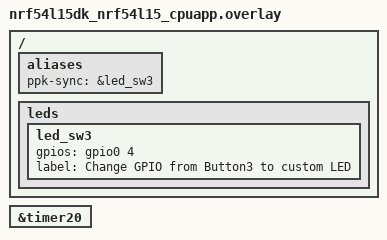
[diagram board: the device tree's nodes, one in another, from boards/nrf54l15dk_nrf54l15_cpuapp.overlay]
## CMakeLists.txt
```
#
# Copyright (c) 2025 Nordic Semiconductor ASA
#
# SPDX-License-Identifier: LicenseRef-Nordic-5-Clause
#

cmake_minimum_required(VERSION 3.20.0)
find_package(Zephyr REQUIRED HINTS $ENV{ZEPHYR_BASE})
project(rram_low_latency)

target_sources(app PRIVATE src/main.c)
```

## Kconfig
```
#
# Copyright (c) 2026 Nordic Semiconductor ASA
#
# SPDX-License-Identifier: LicenseRef-Nordic-5-Clause
#

choice RRAMC_LOW_LATENCY_METHOD
	prompt "Select method that sets RRAMC low latency"
	default RRAMC_POWER_MODE

config RRAMC_POWER_MODE
	bool "RRAMC mode is set to low penalty/high current consumption"

config RRAMC_PPI_WAKEUP
	bool "RRAMC is waken up just before registered event"

endchoice

source "Kconfig.zephyr"
```

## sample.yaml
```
common:
  sysbuild: true
  tags:
    - ci_tests_benchmarks_current_consumption
    - ppk_power_measure
  harness: pytest
  harness_config:
    fixture: ppk_power_measure
    pytest_root:
      - "${CUSTOM_ROOT_TEST_DIR}/test_measure_power_consumption.py::test_measure_and_data_dump_rram_low_latency"
  platform_allow:
    - nrf54l15dk/nrf54l15/cpuapp
    - nrf54lm20dk/nrf54lm20a/cpuapp
    - nrf54lm20dk/nrf54lm20b/cpuapp
    - nrf54ls05dk/nrf54ls05a/cpuapp
    - nrf54ls05dk/nrf54ls05b/cpuapp
    - nrf54lv10dk/nrf54lv10a/cpuapp
    - nrf54lc10dk/nrf54lc10a/cpuapp
  integration_platforms:
    - nrf54l15dk/nrf54l15/cpuapp
tests:
  # Set NRF_RRAMC_LP_STANDBY mode
  # this configuration shall have higher power consumption
  # due to RRAM being powered on for all the time
  benchmarks.current_consumption.rram_low_latency.standby_mode: {}
  # use GRTC and DPPI to wakeup RRAM just before expected event
  benchmarks.current_consumption.rram_low_latency.pre_wake:
    extra_configs:
      - CONFIG_RRAMC_PPI_WAKEUP=y
```

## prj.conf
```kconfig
CONFIG_NRF_SYS_EVENT=y
CONFIG_COUNTER=y
CONFIG_GPIO=y

CONFIG_ASSERT=y

CONFIG_PM=y
CONFIG_POWEROFF=y

# Enable runtime power management for peripheral
CONFIG_PM_DEVICE=y
CONFIG_PM_DEVICE_RUNTIME=y

# Enable for debugging purposes only
CONFIG_BOOT_BANNER=n
CONFIG_NCS_BOOT_BANNER=n
CONFIG_PRINTK=n
CONFIG_LOG=n
CONFIG_CONSOLE=n
CONFIG_UART_CONSOLE=n
CONFIG_SERIAL=n
```

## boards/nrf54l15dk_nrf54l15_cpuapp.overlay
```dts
/*
 * Copyright (c) 2026 Nordic Semiconductor ASA
 *
 * SPDX-License-Identifier: LicenseRef-Nordic-5-Clause
 */

/* PPK takes cpuapp active/sleep state from P0.04
 * which is Button3 in the board definition.
 * However, Buttons have (GPIO_PULL_UP | GPIO_ACTIVE_LOW).
 * Thus, redefine P0.04 as LED.
 */

/ {
	aliases {
		ppk-sync = &led_sw3;
		/delete-property/ sw3;
	};
};

/delete-node/ &button3;

/ {
	leds {
		led_sw3: led_sw3 {
			gpios = <&gpio0 4 GPIO_ACTIVE_HIGH>;
			label = "Change GPIO from Button3 to custom LED";
		};
	};
};

sample_counter: &timer20 {
	status = "okay";
};
```

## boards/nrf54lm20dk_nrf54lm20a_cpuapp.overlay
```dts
/*
 * Copyright (c) 2026 Nordic Semiconductor ASA
 *
 * SPDX-License-Identifier: LicenseRef-Nordic-5-Clause
 */

/ {
	aliases {
		ppk-sync = &led0;
		/delete-property/ led1;
	};
};

/delete-node/ &led1;

sample_counter: &timer20 {
	status = "okay";
};
```

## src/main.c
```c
/*
 * Copyright (c) 2026 Nordic Semiconductor ASA
 *
 * SPDX-License-Identifier: LicenseRef-Nordic-5-Clause
 */

#include <zephyr/logging/log.h>
LOG_MODULE_REGISTER(rram_low_latency, LOG_LEVEL_INF);

#include <nrf_sys_event.h>
#include <zephyr/drivers/counter.h>
#include <zephyr/drivers/gpio.h>
#include <zephyr/cache.h>

/* Sleep duration in us. */
#define DELAY 10000

static const struct device *counter = DEVICE_DT_GET(DT_NODELABEL(sample_counter));
static const struct gpio_dt_spec ppk_sync = GPIO_DT_SPEC_GET(DT_ALIAS(ppk_sync), gpios);

static void counter_handler(const struct device *counter_dev, uint8_t ch_id,
			    uint32_t ticks, void *user_data)
{
	k_sem_give((struct k_sem *)user_data);
}

int main(void)
{
	struct counter_alarm_cfg alarm_cfg;
	struct k_sem sem;
	int event_handle;
	int ret;

	ret = gpio_is_ready_dt(&ppk_sync);
	if (!ret) {
		LOG_ERR("ppk_sync device not ready");
	}
	__ASSERT_NO_MSG(ret == true);

	ret = gpio_pin_configure_dt(&ppk_sync, GPIO_OUTPUT_ACTIVE);
	if (ret != 0) {
		LOG_ERR("Could not configure ppk_sync GPIO (%d)", ret);
	}
	__ASSERT_NO_MSG(ret == 0);

	ret = k_sem_init(&sem, 0, 1);
	if (ret != 0) {
		LOG_ERR("k_sem_init() has failed (%d)", ret);
	}
	__ASSERT_NO_MSG(ret == 0);

	ret = counter_start(counter);
	if (ret != 0) {
		LOG_ERR("counter_start() has failed (%d)", ret);
	}
	__ASSERT_NO_MSG(ret == 0);

	alarm_cfg.flags = 0;
	alarm_cfg.ticks = counter_us_to_ticks(counter, DELAY);
	alarm_cfg.callback = counter_handler;
	alarm_cfg.user_data = &sem;

	/* Only for CI purposes. */
	k_busy_wait(1500000);

	LOG_DBG("Entering main loop");

	while (1) {
		sys_cache_instr_invd_all();
#if defined(CONFIG_RRAMC_POWER_MODE)
		event_handle = nrf_sys_event_register(0, true);
#elif defined(CONFIG_RRAMC_PPI_WAKEUP)
		/* Event is delayed because it is registered early and not as it should just
		 * before starting. Triggering event too early may result in RRAMC going back
		 * to sleep before actual event wakes up the CPU.
		 */
		uint32_t delay_adj = 8;

		event_handle = nrf_sys_event_register(DELAY + delay_adj, true);
		if (event_handle == 32) {
			LOG_ERR("nrf_sys_event_register() has failed (%d)", ret);
		}
		__ASSERT_NO_MSG(event_handle != 32);
#else
#error Unknown RRAMC_LOW_LATENCY_METHOD
#endif
		if (event_handle < 0) {
			LOG_ERR("nrf_sys_event_register() has failed (%d)", ret);
		}
		__ASSERT_NO_MSG(event_handle >= 0);

		/* Configure timer alarm (the event). */
		ret = counter_set_channel_alarm(counter, 0, &alarm_cfg);
		if (ret != 0) {
			LOG_ERR("counter_set_channel_alarm() has failed (%d)", ret);
		}
		__ASSERT_NO_MSG(ret >= 0);

		/* Indicate going to sleep. */
		gpio_pin_set_dt(&ppk_sync, 0);

		LOG_DBG("Going to sleep");

		/* Wait for the event. */
		ret = k_sem_take(&sem, K_USEC(DELAY + 100));
		if (ret != 0) {
			LOG_ERR("k_sem_take() has failed (%d)", ret);
		}
		__ASSERT_NO_MSG(ret >= 0);

		/* Indicate PM active state */
		gpio_pin_set_dt(&ppk_sync, 1);

		LOG_DBG("Woken up");

		ret = nrf_sys_event_unregister(event_handle, false);
		if (ret != 0) {
			LOG_ERR("nrf_sys_event_unregister() has failed (%d)", ret);
		}
		__ASSERT_NO_MSG(ret == 0);

		k_busy_wait(DELAY >> 1);
	}

	return 0;
}
```
